AUTOSAR XML (schema 4-2-1)
package /ComponentTypes
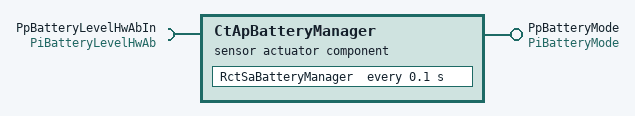
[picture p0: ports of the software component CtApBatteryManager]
  sensor actuator sw component type CtApBatteryManager
    provide port PpBatteryMode: mode-switch-sender-com-spec{enhanced-mode-api=false, mode-group=BatteryMode, queue-length=1}, provided-interface=PiBatteryMode
    require port PpBatteryLevelHwAbIn: required-interface=PiBatteryLevelHwAb
    behavior CtApBatteryManager_InternalBehavior
      timing event TMT_RctSaBatteryManager: start-on-event=RctSaBatteryManager, period=0.1
      runnable RctSaBatteryManager
        mode switch point SWITCH_PpBatteryMode_BatteryMode: mode-group=PpBatteryMode.BatteryMode
        sync call SC_PpBatteryLevelHwAbIn_ReadChannel: operation=PpBatteryLevelHwAbIn.ReadChannel, timeout=0
  swc implementation CtApBatteryManager_Implementation: behavior=CtApBatteryManager_InternalBehavior
    code-descriptors:
      code Default: artifact-descriptors=autosar-engineering-object={short-label=Default, category=SWSRC}
